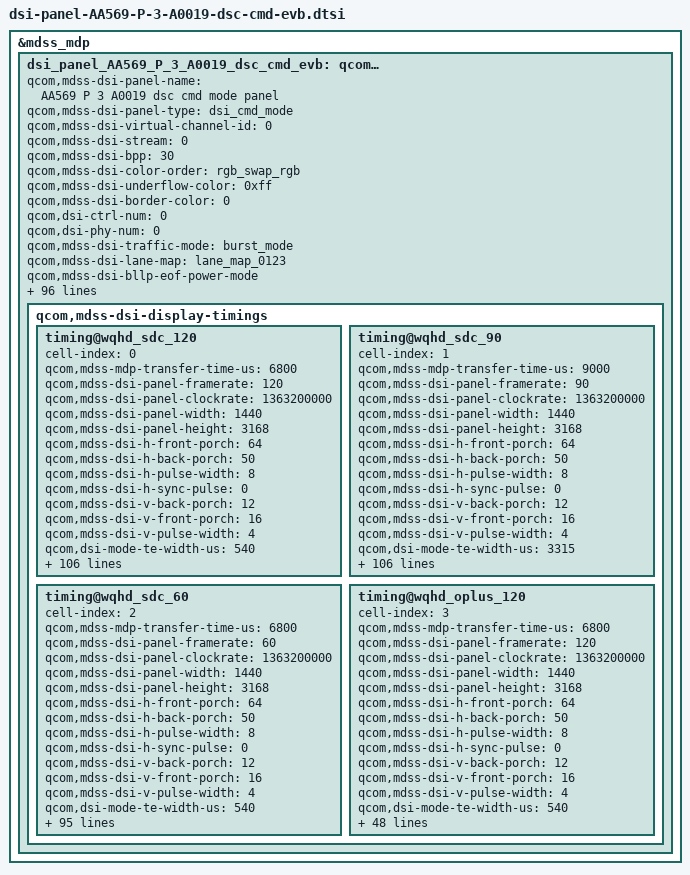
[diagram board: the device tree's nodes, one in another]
&mdss_mdp {
	dsi_panel_AA569_P_3_A0019_dsc_cmd_evb: qcom,mdss_dsi_panel_AA569_P_3_A0019_dsc_cmd_evb {
		qcom,mdss-dsi-panel-name = "AA569 P 3 A0019 dsc cmd mode panel";
		qcom,mdss-dsi-panel-type = "dsi_cmd_mode";
		qcom,mdss-dsi-virtual-channel-id = <0>;
		qcom,mdss-dsi-stream = <0>;
		qcom,mdss-dsi-bpp = <30>;
		qcom,mdss-dsi-color-order = "rgb_swap_rgb";
		qcom,mdss-dsi-underflow-color = <0xff>;
		qcom,mdss-dsi-border-color = <0>;
		qcom,dsi-ctrl-num = <0>;
		qcom,dsi-phy-num = <0>;
		qcom,mdss-dsi-traffic-mode = "burst_mode";
		qcom,mdss-dsi-lane-map = "lane_map_0123";
		qcom,mdss-dsi-bllp-eof-power-mode;
		qcom,mdss-dsi-bllp-power-mode;
		qcom,mdss-dsi-lane-0-state;
		qcom,mdss-dsi-lane-1-state;
		qcom,mdss-dsi-lane-2-state;
		qcom,mdss-dsi-lane-3-state;
		qcom,mdss-dsi-dma-trigger = "trigger_sw";
		qcom,mdss-dsi-mdp-trigger = "none";
		qcom,mdss-dsi-reset-sequence = <1 10>, <0 5>, <1 30>;
		qcom,mdss-pan-physical-width-dimension = <71>;
		qcom,mdss-pan-physical-height-dimension = <158>;
		qcom,mdss-dsi-te-check-enable;
		qcom,mdss-dsi-te-using-te-pin;
		qcom,mdss-dsi-te-pin-select = <1>;
		qcom,mdss-dsi-te-dcs-command = <1>;
		qcom,mdss-dsi-wr-mem-start = <0x2C>;
		qcom,mdss-dsi-wr-mem-continue = <0x3C>;
		//qcom,mdss-dsi-lp11-init;
		qcom,mdss-dsi-init-delay-us = <1000>;
		qcom,mdss-dsi-panel-jitter = <0x4 0x1>;
		/* HDR Setting */
		qcom,mdss-dsi-panel-hdr-enabled;
		qcom,mdss-dsi-panel-hdr-color-primaries = <15635 16450 34000 16000 13250 34500 7500 3000>;
		qcom,mdss-dsi-panel-peak-brightness = <14000000>;
		qcom,mdss-dsi-panel-average-brightness = <2000000>;
		qcom,mdss-dsi-panel-blackness-level = <2000>;

		qcom,mdss-dsi-display-timings {
			timing@wqhd_sdc_120 {
				#include "dsi-panel-AA569-P-3-A0019-common.dtsi"
				#include "dsi-panel-AA569-P-3-A0019-loading-effect-evb.dtsi"
				cell-index = <0>;
				qcom,mdss-mdp-transfer-time-us = <6800>;
				qcom,mdss-dsi-panel-framerate = <120>;
				qcom,mdss-dsi-panel-clockrate = <1363200000>;
				qcom,mdss-dsi-panel-width = <1440>;
				qcom,mdss-dsi-panel-height = <3168>;
				qcom,mdss-dsi-h-front-porch = <64>;
				qcom,mdss-dsi-h-back-porch = <50>;
				qcom,mdss-dsi-h-pulse-width = <8>;
				qcom,mdss-dsi-h-sync-pulse = <0>;
				qcom,mdss-dsi-v-back-porch = <12>;
				qcom,mdss-dsi-v-front-porch = <16>;
				qcom,mdss-dsi-v-pulse-width = <4>;
				qcom,dsi-mode-te-width-us = <540>;

				qcom,mdss-dsi-timing-switch-command = [
					//120Hz
					39 00 00 40 00 00 04 FF 5A A5 00
					15 00 00 40 00 00 02 60 00
					39 00 00 40 00 00 04 FF 5A A5 2D
					39 00 00 40 00 00 03 83 00 00
					15 00 00 40 00 00 02 F2 00
					39 00 00 40 00 00 04 FF 5A A5 02
					39 00 00 40 00 00 04 B0 01 80 00
					39 00 00 00 00 00 04 FF 5A A5 00
				];
				qcom,mdss-dsi-on-command = [
					//120Hz
					39 00 00 40 00 00 04 FF 5A A5 00
					15 00 00 40 00 00 02 60 00
					39 00 00 40 00 00 04 FF 5A A5 2D
					15 00 00 40 00 00 03 ED 03 00
					15 00 00 40 00 00 03 83 00 00
					15 00 00 40 00 00 02 F2 00
					39 00 00 40 00 00 04 FF 5A A5 02
					39 00 00 40 00 00 04 B0 01 80 00
					//light on
					39 00 00 40 00 00 04 FF 5A A5 00
					15 00 00 40 00 00 02 5A 01
					15 00 00 40 00 00 02 5B 80
					39 00 00 40 00 00 04 FF 5A A5 2D
					39 00 00 40 00 00 04 EC 01 FF FF
					39 00 00 40 00 00 03 ED D5 00
					39 00 00 40 00 00 03 93 A0 00
					39 00 00 40 00 00 03 94 40 00
					39 00 00 40 00 00 03 95 15 00
					39 00 00 40 00 00 03 96 FD 00
					39 00 00 40 00 00 04 FF 5A A5 02
					15 00 00 40 00 00 02 B6 00
					39 00 00 40 00 00 04 FF 5A A5 2D
					15 00 00 40 00 00 02 CE D4
					15 00 00 40 00 00 02 F7 40
					15 00 00 00 00 00 02 D9 41
					39 00 00 40 00 00 04 FF 5A A5 10
					15 00 00 40 00 00 02 83 2B
					39 00 00 40 00 00 04 FF 5A A5 20
					15 00 00 00 00 00 02 E1 80
					//esd check
					39 00 00 40 00 00 04 FF 5A A5 08
					15 00 00 40 00 00 02 D2 05
					15 00 00 40 00 00 02 D3 0D
					15 00 00 40 00 00 02 D4 40
					15 00 00 40 00 00 02 F5 55
					15 00 00 00 00 00 02 F6 18
					//120hz setting
					39 00 00 40 00 00 04 FF 5A A5 00
					15 00 00 40 00 00 02 5E 01				//Skip Frame en
					15 00 00 40 00 00 02 60 00				//Normal mode 1 = 120Hz.
					15 00 00 40 00 00 02 61 0D				//AOD in Mode 14 30Hz
					15 00 00 40 00 00 02 6D 01				//IRC Enable
					15 00 00 40 00 00 02 35 00
					15 00 00 40 00 00 02 53 20
					39 00 00 00 00 00 05 51 0D BB 0D BB
					/* spr in ap */
					39 00 00 40 00 00 04 FF 5A A5 14
					15 00 00 40 00 00 02 82 01		//SPR IN AP MODE
					39 00 00 40 00 00 04 FF 5A A5 07
					15 00 00 40 00 00 02 91 03		//CR CB SETTING
					15 00 00 40 00 00 02 8A 01         //DSC ON
					39 00 00 40 00 00 64 80 00 00 00 00 00 12 00 00 A0
					                     20 E0 0C 60 05 A0 00 0C 02 D0
					                     02 76 01 9A 01 1E 00 19 01 2B
					                     00 07 00 0C 08 BB 10 17 16 00
					                     0A E4 07 10 20 00 06 0F 0F 33
					                     0E 1C 2A 38 46 54 62 69 70 77
					                     79 7B 7D 7E 01 C2 22 00 2A 40
					                     32 BE 3A FC 3A FA 3A F8 3B 38
					                     3B 78 3B 76 4B B6 4B B6 4B F4
					                     5B F4 7C 34 01 00 00 00 00 00
					39 00 00 00 00 00 04 FF 5A A5 00
					//RCN
					39 00 00 40 00 00 04 FF 5A A5 17
					39 00 00 40 00 00 26 FA 01 20 00 3F 00 00 00 00 1C 20 00 3F 00 20 00 00 00 00 00 19 1C 20 00 00 00 20 00 00 00 00 14 19 1C 20 00 00 00
					39 00 00 40 00 00 0D FB 00 00 00 0A 50 FA 0A 50 64 00 00 00
					39 00 00 40 00 00 11 FC 00 00 00 00 00 00 00 00 00 00 00 00 00 00 00 00
					39 00 00 00 00 00 04 FF 5A A5 00
					//Hole
					39 00 00 40 00 00 04 FF 5A A5 13
					39 00 00 40 00 00 20 F7 01 00 00 00 19 00 00 19 00 00 00 00 00 00 00 00 19 00 00 00 19 00 19 19 00 19 00 00 19 00 19
					39 00 00 00 00 00 04 FF 5A A5 00

					15 00 00 00 78 00 02 11 00
					15 00 00 00 00 00 02 29 00
				];

				//qcom,panel-roi-alignment=<1080 44 1080 44 1080 44>;
				//qcom,partial-update-enabled = "single_roi";

				qcom,lm-split = <720 720>;
				qcom,mdss-dsc-slice-height = <22>;
				qcom,mdss-dsc-slice-width = <720>;
			};
			timing@wqhd_sdc_90 {
				#include "dsi-panel-AA569-P-3-A0019-common.dtsi"
				#include "dsi-panel-AA569-P-3-A0019-loading-effect-evb.dtsi"
				cell-index = <1>;
				qcom,mdss-mdp-transfer-time-us = <9000>;
				qcom,mdss-dsi-panel-framerate = <90>;
				qcom,mdss-dsi-panel-clockrate = <1363200000>;
				qcom,mdss-dsi-panel-width = <1440>;
				qcom,mdss-dsi-panel-height = <3168>;
				qcom,mdss-dsi-h-front-porch = <64>;
				qcom,mdss-dsi-h-back-porch = <50>;
				qcom,mdss-dsi-h-pulse-width = <8>;
				qcom,mdss-dsi-h-sync-pulse = <0>;
				qcom,mdss-dsi-v-back-porch = <12>;
				qcom,mdss-dsi-v-front-porch = <16>;
				qcom,mdss-dsi-v-pulse-width = <4>;
				qcom,dsi-mode-te-width-us = <3315>;

				qcom,mdss-dsi-timing-switch-command = [
					//90Hz
					39 00 00 40 00 00 04 FF 5A A5 00
					15 00 00 40 00 00 02 60 07
					39 00 00 40 00 00 04 FF 5A A5 2D
					39 00 00 40 00 00 03 8A 00 00
					15 00 00 40 00 00 02 F2 00
					39 00 00 40 00 00 04 FF 5A A5 02
					39 00 00 40 00 00 04 B0 00 80 00
					39 00 00 00 00 00 04 FF 5A A5 00
				];
				qcom,mdss-dsi-on-command = [
					//90Hz
					39 00 00 40 00 00 04 FF 5A A5 00
					15 00 00 40 00 00 02 60 07
					39 00 00 40 00 00 04 FF 5A A5 2D
					39 00 00 40 00 00 03 ED 0C 20
					39 00 00 40 00 00 03 8A 00 00
					15 00 00 40 00 00 02 84 00
					39 00 00 40 00 00 04 FF 5A A5 02
					39 00 00 40 00 00 04 B0 00 80 00
					//light on
					39 00 00 40 00 00 04 FF 5A A5 00
					15 00 00 40 00 00 02 5A 01
					15 00 00 40 00 00 02 5B 80
					39 00 00 40 00 00 04 FF 5A A5 2D
					39 00 00 40 00 00 04 EC 01 FF FF
					39 00 00 40 00 00 03 ED D5 00
					39 00 00 40 00 00 03 93 A0 00
					39 00 00 40 00 00 03 94 40 00
					39 00 00 40 00 00 03 95 15 00
					39 00 00 40 00 00 03 96 FD 00
					39 00 00 40 00 00 04 FF 5A A5 02
					15 00 00 40 00 00 02 B6 00
					39 00 00 40 00 00 04 FF 5A A5 2D
					15 00 00 40 00 00 02 CE D4
					15 00 00 40 00 00 02 F7 40
					15 00 00 40 00 00 02 D9 41
					39 00 00 40 00 00 04 FF 5A A5 10
					15 00 00 40 00 00 02 83 2B
					39 00 00 40 00 00 04 FF 5A A5 20
					15 00 00 00 00 00 02 E1 80
					//esd check
					39 00 00 40 00 00 04 FF 5A A5 08
					15 00 00 40 00 00 02 D2 05
					15 00 00 40 00 00 02 D3 0D
					15 00 00 40 00 00 02 D4 40
					15 00 00 40 00 00 02 F5 55
					15 00 00 00 00 00 02 F6 18
					//90hz setting
					39 00 00 40 00 00 04 FF 5A A5 00
					15 00 00 40 00 00 02 5E 01
					15 00 00 40 00 00 02 60 07
					15 00 00 40 00 00 02 61 0D
					15 00 00 40 00 00 02 6D 01
					15 00 00 40 00 00 02 35 00
					15 00 00 40 00 00 02 53 20
					39 00 00 00 00 00 05 51 0D BB 0D BB
					/* spr in ap */
					39 00 00 40 00 00 04 FF 5A A5 14
					15 00 00 40 00 00 02 82 01		//SPR IN AP MODE
					39 00 00 40 00 00 04 FF 5A A5 07
					15 00 00 40 00 00 02 91 03		//CR CB SETTING
					15 00 00 40 00 00 02 8A 01         //DSC ON
					39 00 00 40 00 00 64 80 00 00 00 00 00 12 00 00 A0
					                     20 E0 0C 60 05 A0 00 0C 02 D0
					                     02 76 01 9A 01 1E 00 19 01 2B
					                     00 07 00 0C 08 BB 10 17 16 00
					                     0A E4 07 10 20 00 06 0F 0F 33
					                     0E 1C 2A 38 46 54 62 69 70 77
					                     79 7B 7D 7E 01 C2 22 00 2A 40
					                     32 BE 3A FC 3A FA 3A F8 3B 38
					                     3B 78 3B 76 4B B6 4B B6 4B F4
					                     5B F4 7C 34 01 00 00 00 00 00
					39 00 00 00 00 00 04 FF 5A A5 00
					//RCN
					39 00 00 40 00 00 04 FF 5A A5 17
					39 00 00 40 00 00 26 FA 01 20 00 3F 00 00 00 00 1C 20 00 3F 00 20 00 00 00 00 00 19 1C 20 00 00 00 20 00 00 00 00 14 19 1C 20 00 00 00
					39 00 00 40 00 00 0D FB 00 00 00 0A 50 FA 0A 50 64 00 00 00
					39 00 00 40 00 00 11 FC 00 00 00 00 00 00 00 00 00 00 00 00 00 00 00 00
					39 00 00 00 00 00 04 FF 5A A5 00
					//Hole
					39 00 00 40 00 00 04 FF 5A A5 13
					39 00 00 40 00 00 20 F7 01 00 00 00 19 00 00 19 00 00 00 00 00 00 00 00 19 00 00 00 19 00 19 19 00 19 00 00 19 00 19
					39 00 00 00 00 00 04 FF 5A A5 00

					15 00 00 00 78 00 02 11 00
					15 00 00 00 00 00 02 29 00
				];

				//qcom,panel-roi-alignment=<1080 44 1080 44 1080 44>;
				//qcom,partial-update-enabled = "single_roi";

				qcom,lm-split = <720 720>;
				qcom,mdss-dsc-slice-height = <22>;
				qcom,mdss-dsc-slice-width = <720>;
			};
			timing@wqhd_sdc_60 {
				#include "dsi-panel-AA569-P-3-A0019-common.dtsi"
				#include "dsi-panel-AA569-P-3-A0019-loading-effect-evb.dtsi"
				cell-index = <2>;
				qcom,mdss-mdp-transfer-time-us = <6800>;
				qcom,mdss-dsi-panel-framerate = <60>;
				qcom,mdss-dsi-panel-clockrate = <1363200000>;
				qcom,mdss-dsi-panel-width = <1440>;
				qcom,mdss-dsi-panel-height = <3168>;
				qcom,mdss-dsi-h-front-porch = <64>;
				qcom,mdss-dsi-h-back-porch = <50>;
				qcom,mdss-dsi-h-pulse-width = <8>;
				qcom,mdss-dsi-h-sync-pulse = <0>;
				qcom,mdss-dsi-v-back-porch = <12>;
				qcom,mdss-dsi-v-front-porch = <16>;
				qcom,mdss-dsi-v-pulse-width = <4>;
				qcom,dsi-mode-te-width-us = <540>;

				/* Apollo vsync config, need to measure TE signal */
				oplus,apollo-panel-vsync-width = <8600>;

				qcom,mdss-dsi-timing-switch-command = [
					//60hz
					39 00 00 40 00 00 04 FF 5A A5 00
					15 00 00 40 00 00 02 60 00
					39 00 00 40 00 00 04 FF 5A A5 2D
					39 00 00 40 00 00 03 83 01 00
					15 00 00 40 00 00 02 F2 01
					39 00 00 40 00 00 04 FF 5A A5 02
					39 00 00 40 00 00 04 B0 01 80 00
					39 00 00 00 00 00 04 FF 5A A5 00
				];
				qcom,mdss-dsi-on-command = [
					//60Hz
					39 00 00 40 00 00 04 FF 5A A5 00
					15 00 00 40 00 00 02 60 00
					39 00 00 40 00 00 04 FF 5A A5 2D
					15 00 00 40 00 00 03 ED 03 00
					15 00 00 40 00 00 03 83 01 00
					15 00 00 40 00 00 02 F2 01
					39 00 00 40 00 00 04 FF 5A A5 02
					39 00 00 40 00 00 04 B0 01 80 00
					//light on
					39 00 00 40 00 00 04 FF 5A A5 00
					15 00 00 40 00 00 02 5A 01
					15 00 00 40 00 00 02 5B 80
					39 00 00 40 00 00 04 FF 5A A5 2D
					39 00 00 40 00 00 04 EC 01 FF FF
					39 00 00 40 00 00 03 ED D5 00
					39 00 00 40 00 00 03 93 A0 00
					39 00 00 40 00 00 03 94 40 00
					39 00 00 40 00 00 03 95 15 00
					39 00 00 40 00 00 03 96 FD 00
					39 00 00 40 00 00 04 FF 5A A5 02
					15 00 00 40 00 00 02 B6 00
					39 00 00 40 00 00 04 FF 5A A5 2D
					15 00 00 40 00 00 02 CE D4
					15 00 00 40 00 00 02 F7 40
					15 00 00 40 00 00 02 D9 41
					39 00 00 40 00 00 04 FF 5A A5 10
					15 00 00 40 00 00 02 83 2B
					39 00 00 40 00 00 04 FF 5A A5 20
					15 00 00 00 00 00 02 E1 80
					//esd check
					39 00 00 40 00 00 04 FF 5A A5 08
					15 00 00 40 00 00 02 D2 05
					15 00 00 40 00 00 02 D3 0D
					15 00 00 40 00 00 02 D4 40
					15 00 00 40 00 00 02 F5 55
					15 00 00 00 00 00 02 F6 18
					//60hz
					39 00 00 40 00 00 04 FF 5A A5 00
					15 00 00 40 00 00 02 5E 01
					15 00 00 40 00 00 02 60 00
					15 00 00 40 00 00 02 61 0D
					15 00 00 40 00 00 02 6D 01
					15 00 00 40 00 00 02 35 00
					15 00 00 40 00 00 02 53 20
					39 00 00 00 00 00 05 51 0D BB 0D BB
					/* spr in ap */
					39 00 00 40 00 00 04 FF 5A A5 14
					15 00 00 40 00 00 02 82 01		//SPR IN AP MODE
					39 00 00 40 00 00 04 FF 5A A5 07
					15 00 00 40 00 00 02 91 03		//CR CB SETTING
					15 00 00 40 00 00 02 8A 01         //DSC ON
					39 00 00 40 00 00 64 80 00 00 00 00 00 12 00 00 A0
					                     20 E0 0C 60 05 A0 00 0C 02 D0
					                     02 76 01 9A 01 1E 00 19 01 2B
					                     00 07 00 0C 08 BB 10 17 16 00
					                     0A E4 07 10 20 00 06 0F 0F 33
					                     0E 1C 2A 38 46 54 62 69 70 77
					                     79 7B 7D 7E 01 C2 22 00 2A 40
					                     32 BE 3A FC 3A FA 3A F8 3B 38
					                     3B 78 3B 76 4B B6 4B B6 4B F4
					                     5B F4 7C 34 01 00 00 00 00 00
					39 00 00 00 00 00 04 FF 5A A5 00
					//RCN
					39 00 00 40 00 00 04 FF 5A A5 17
					39 00 00 40 00 00 26 FA 01 20 00 3F 00 00 00 00 1C 20 00 3F 00 20 00 00 00 00 00 19 1C 20 00 00 00 20 00 00 00 00 14 19 1C 20 00 00 00
					39 00 00 40 00 00 0D FB 00 00 00 0A 50 FA 0A 50 64 00 00 00
					39 00 00 40 00 00 11 FC 00 00 00 00 00 00 00 00 00 00 00 00 00 00 00 00
					39 00 00 00 00 00 04 FF 5A A5 00
					//Hole
					39 00 00 40 00 00 04 FF 5A A5 13
					39 00 00 40 00 00 20 F7 01 00 00 00 19 00 00 19 00 00 00 00 00 00 00 00 19 00 00 00 19 00 19 19 00 19 00 00 19 00 19
					39 00 00 00 00 00 04 FF 5A A5 00

					15 00 00 00 78 00 02 11 00
					15 00 00 00 00 00 02 29 00
				];

				//qcom,panel-roi-alignment=<1080 44 1080 44 1080 44>;
				//qcom,partial-update-enabled = "single_roi";

				qcom,lm-split = <720 720>;
				qcom,mdss-dsc-slice-height = <22>;
				qcom,mdss-dsc-slice-width = <720>;
				oplus,apollo-panel-async-bl-delay = <9000>;
			};
			timing@wqhd_oplus_120 {
				#include "dsi-panel-AA569-P-3-A0019-common.dtsi"
				#include "dsi-panel-AA569-P-3-A0019-loading-effect-evb.dtsi"
				cell-index = <3>;
				qcom,mdss-mdp-transfer-time-us = <6800>;
				qcom,mdss-dsi-panel-framerate = <120>;
				qcom,mdss-dsi-panel-clockrate = <1363200000>;
				qcom,mdss-dsi-panel-width = <1440>;
				qcom,mdss-dsi-panel-height = <3168>;
				qcom,mdss-dsi-h-front-porch = <64>;
				qcom,mdss-dsi-h-back-porch = <50>;
				qcom,mdss-dsi-h-pulse-width = <8>;
				qcom,mdss-dsi-h-sync-pulse = <0>;
				qcom,mdss-dsi-v-back-porch = <12>;
				qcom,mdss-dsi-v-front-porch = <16>;
				qcom,mdss-dsi-v-pulse-width = <4>;
				qcom,dsi-mode-te-width-us = <540>;

				qcom,mdss-dsi-timing-switch-command = [
					//OA-120Hz
					39 00 00 40 00 00 04 FF 5A A5 00
					15 00 00 40 00 00 02 60 00
					39 00 00 40 00 00 04 FF 5A A5 2D
					39 00 00 40 00 00 04 EC 01 0A 20
					39 00 00 40 00 00 03 ED 03 00
					39 00 00 40 00 00 19 EF 00 00 00 00 00 00 00 00 00 00 00 00 00 00 00 01 00 00 00 00 02 00 00 00
					15 00 00 40 00 00 02 F2 00
					39 00 00 40 00 00 04 FF 5A A5 02
					39 00 00 40 00 00 05 C0 03 00 02 00
					39 00 00 40 00 00 04 B0 00 88 00
					39 00 00 40 00 00 04 FF 5A A5 4F
					15 00 00 00 00 00 02 8B 78
				];
				qcom,mdss-dsi-on-command = [
					//OA-120Hz
					39 00 00 40 00 00 04 FF 5A A5 00
					15 00 00 40 00 00 02 60 00
					39 00 00 40 00 00 04 FF 5A A5 2D
					15 00 00 40 00 00 04 EC 01 0A 20
					15 00 00 40 00 00 03 ED 03 00
					15 00 00 40 00 00 19 EF 00 00 00 00 00 00 00 00 00 00 00 00 00 00 00 01 00 00 00 00 02 00 00 00
					15 00 00 40 00 00 02 F2 01
					39 00 00 40 00 00 04 FF 5A A5 02
					39 00 00 40 00 00 05 C0 03 00 02 00
					39 00 00 40 00 00 04 B0 00 88 00
					//light on
					39 00 00 40 00 00 04 FF 5A A5 00
					15 00 00 40 00 00 02 5A 01
					15 00 00 40 00 00 02 5B 80
					39 00 00 40 00 00 04 FF 5A A5 2D
					39 00 00 40 00 00 04 EC 01 FF FF
					39 00 00 40 00 00 03 ED D5 00
					39 00 00 40 00 00 03 93 A0 00
					39 00 00 40 00 00 03 94 40 00
					39 00 00 40 00 00 03 95 15 00
					39 00 00 40 00 00 03 96 FD 00
					39 00 00 40 00 00 04 FF 5A A5 02
					15 00 00 40 00 00 02 B6 00
					39 00 00 40 00 00 04 FF 5A A5 2D
					15 00 00 40 00 00 02 CE D4
					15 00 00 40 00 00 02 F7 40
					15 00 00 40 00 00 02 D9 41
					39 00 00 40 00 00 04 FF 5A A5 10
					15 00 00 40 00 00 02 83 2B
					39 00 00 40 00 00 04 FF 5A A5 20
					15 00 00 00 00 00 02 E1 80
					//esd check
					39 00 00 40 00 00 04 FF 5A A5 08
					15 00 00 40 00 00 02 D2 05
					15 00 00 40 00 00 02 D3 0D
					15 00 00 40 00 00 02 D4 40
					15 00 00 40 00 00 02 F5 55
					15 00 00 00 00 00 02 F6 18
					//oa 120
					39 00 00 40 00 00 04 FF 5A A5 00
					15 00 00 40 00 00 02 5E 01
					15 00 00 40 00 00 02 60 00
					15 00 00 40 00 00 02 61 0D
					15 00 00 40 00 00 02 6D 01
					15 00 00 40 00 00 02 35 00
					15 00 00 40 00 00 02 53 20
					39 00 00 00 00 00 05 51 0D BB 0D BB
					/* spr in ap */
					39 00 00 40 00 00 04 FF 5A A5 14
					15 00 00 40 00 00 02 82 01		//SPR IN AP MODE
					39 00 00 40 00 00 04 FF 5A A5 07
					15 00 00 40 00 00 02 91 03		//CR CB SETTING
					15 00 00 40 00 00 02 8A 01         //DSC ON
					39 00 00 40 00 00 64 80 00 00 00 00 00 12 00 00 A0
					                     20 E0 0C 60 05 A0 00 0C 02 D0
					                     02 76 01 9A 01 1E 00 19 01 2B
					                     00 07 00 0C 08 BB 10 17 16 00
					                     0A E4 07 10 20 00 06 0F 0F 33
					                     0E 1C 2A 38 46 54 62 69 70 77
					                     79 7B 7D 7E 01 C2 22 00 2A 40
					                     32 BE 3A FC 3A FA 3A F8 3B 38
					                     3B 78 3B 76 4B B6 4B B6 4B F4
					                     5B F4 7C 34 01 00 00 00 00 00
					39 00 00 00 00 00 04 FF 5A A5 00
					//RCN
					39 00 00 40 00 00 04 FF 5A A5 17
					39 00 00 40 00 00 26 FA 01 20 00 3F 00 00 00 00 1C 20 00 3F 00 20 00 00 00 00 00 19 1C 20 00 00 00 20 00 00 00 00 14 19 1C 20 00 00 00
					39 00 00 40 00 00 0D FB 00 00 00 0A 50 FA 0A 50 64 00 00 00
					39 00 00 40 00 00 11 FC 00 00 00 00 00 00 00 00 00 00 00 00 00 00 00 00
					39 00 00 00 00 00 04 FF 5A A5 00
					//Hole
					39 00 00 40 00 00 04 FF 5A A5 13
					39 00 00 40 00 00 20 F7 01 00 00 00 19 00 00 19 00 00 00 00 00 00 00 00 19 00 00 00 19 00 19 19 00 19 00 00 19 00 19
					39 00 00 00 00 00 04 FF 5A A5 00

					15 00 00 00 78 00 02 11 00
					15 00 00 00 00 00 02 29 00
				];

				//qcom,panel-roi-alignment=<1080 44 1080 44 1080 44>;
				//qcom,partial-update-enabled = "single_roi";

				qcom,lm-split = <720 720>;
				qcom,mdss-dsc-slice-height = <22>;
				qcom,mdss-dsc-slice-width = <720>;
			};
		};
	};
};

&dsi_panel_AA569_P_3_A0019_dsc_cmd_evb {
	qcom,ulps-enabled;
	qcom,dsi-select-clocks = "pll_byte_clk0", "pll_dsi_clk0";
	qcom,mdss-dsi-display-timings {
		timing@wqhd_sdc_120 {
			qcom,mdss-dsi-panel-phy-timings = [00 2C 0C 0C 1D 1A 0C 0C 0B 02 04 00 24 11];
			qcom,display-topology = <1 1 1>,<2 2 1>;
			qcom,default-topology-index = <1>;
			qcom,partial-update-enabled = "single_roi";
			qcom,panel-roi-alignment = <1440 22 1440 22 1440 22>;
		};
		timing@wqhd_sdc_90 {
			qcom,mdss-dsi-panel-phy-timings = [00 2C 0C 0C 1D 1A 0C 0C 0B 02 04 00 24 11];
			qcom,display-topology = <1 1 1>,<2 2 1>;
			qcom,default-topology-index = <1>;
			qcom,partial-update-enabled = "single_roi";
			qcom,panel-roi-alignment = <1440 22 1440 22 1440 22>;
		};
		timing@wqhd_sdc_60 {
			qcom,mdss-dsi-panel-phy-timings = [00 2C 0C 0C 1D 1A 0C 0C 0B 02 04 00 24 11];
			qcom,display-topology = <1 1 1>,<2 2 1>;
			qcom,default-topology-index = <1>;
			qcom,partial-update-enabled = "single_roi";
			qcom,panel-roi-alignment = <1440 22 1440 22 1440 22>;
		};
		timing@wqhd_oplus_120 {
			qcom,mdss-dsi-panel-phy-timings = [00 2C 0C 0C 1D 1A 0C 0C 0B 02 04 00 24 11];
			qcom,display-topology = <1 1 1>,<2 2 1>;
			qcom,default-topology-index = <1>;
			qcom,partial-update-enabled = "single_roi";
			qcom,panel-roi-alignment = <1440 22 1440 22 1440 22>;
		};
	};
};

&dsi_panel_AA569_P_3_A0019_dsc_cmd_evb {
	qcom,mdss-dsi-display-timings {
		timing@wqhd_sdc_120 {
			/* SDC ADFR */
			qcom,mdss-dsi-h-sync-skew = <0>;
			oplus,adfr-min-fps-mapping-table = <120 60 30 20 10 5 1>;
			oplus,adfr-idle-off-min-fps = <20>;
			qcom,mdss-dsi-adfr-pre-switch-command = [
				39 00 00 40 00 00 04 FF 5A A5 2D
				39 00 00 40 00 00 03 ED 01 00
				39 00 00 40 00 00 03 83 00 00
				39 00 00 40 00 00 03 8E 00 00
				15 00 00 40 00 00 02 97 00
				15 00 00 40 00 00 02 98 00
				39 00 00 40 00 00 03 A0 00 00
				39 00 00 00 00 00 04 FF 5A A5 00
			];
			qcom,mdss-dsi-adfr-min-fps-0-command = [
				/*120Hz*/
				39 00 00 40 00 00 04 FF 5A A5 2D
				39 00 00 40 00 00 03 ED 01 00
				39 00 00 40 00 00 03 83 00 00
				15 00 00 40 00 00 02 97 00
				15 00 00 40 00 00 02 98 00
				39 00 00 40 00 00 03 A0 00 00
				39 00 00 00 00 00 04 FF 5A A5 00
			];
			qcom,mdss-dsi-adfr-min-fps-1-command = [
				/*60Hz*/
				39 00 00 40 00 00 04 FF 5A A5 2D
				39 00 00 40 00 00 03 ED 01 00
				39 00 00 40 00 00 03 83 01 00
				15 00 00 40 00 00 02 97 00
				15 00 00 40 00 00 02 98 01
				39 00 00 40 00 00 03 A0 00 00
				39 00 00 00 00 00 04 FF 5A A5 00
			];
			qcom,mdss-dsi-adfr-min-fps-2-command = [
				/*30Hz*/
				39 00 00 40 00 00 04 FF 5A A5 2D
				39 00 00 40 00 00 03 ED 01 00
				39 00 00 40 00 00 03 83 03 00
				15 00 00 40 00 00 02 97 00
				15 00 00 40 00 00 02 98 03
				39 00 00 40 00 00 03 A0 00 00
				39 00 00 00 00 00 04 FF 5A A5 00
			];
			qcom,mdss-dsi-adfr-min-fps-3-command = [
				/*20Hz*/
				39 00 00 40 00 00 04 FF 5A A5 2D
				39 00 00 40 00 00 03 ED 01 00
				39 00 00 40 00 00 03 83 05 00
				15 00 00 40 00 00 02 97 00
				15 00 00 40 00 00 02 98 03
				39 00 00 40 00 00 03 A0 00 00
				39 00 00 00 00 00 04 FF 5A A5 00
			];
			qcom,mdss-dsi-adfr-min-fps-4-command = [
				/*10Hz*/
				39 00 00 40 00 00 04 FF 5A A5 2D
				39 00 00 40 00 00 03 ED 01 00
				39 00 00 40 00 00 03 83 0B 00
				15 00 00 40 00 00 02 97 00
				15 00 00 40 00 00 02 98 03
				39 00 00 40 00 00 03 A0 00 00
				39 00 00 00 00 00 04 FF 5A A5 00
			];
			qcom,mdss-dsi-adfr-min-fps-5-command = [
				/*5Hz*/
				39 00 00 40 00 00 04 FF 5A A5 2D
				39 00 00 40 00 00 03 ED 01 00
				39 00 00 40 00 00 03 83 17 00
				15 00 00 40 00 00 02 97 00
				15 00 00 40 00 00 02 98 03
				39 00 00 40 00 00 03 A0 00 00
				39 00 00 00 00 00 04 FF 5A A5 00
			];
			qcom,mdss-dsi-adfr-min-fps-6-command = [
				/*1Hz*/
				39 00 00 40 00 00 04 FF 5A A5 2D
				39 00 00 40 00 00 03 ED 01 00
				39 00 00 40 00 00 03 83 77 00
				15 00 00 40 00 00 02 97 02
				15 00 00 40 00 00 02 98 03
				15 00 00 40 00 00 02 99 0B
				15 00 00 40 00 00 02 9A 17
				39 00 00 40 00 00 03 A0 00 02
				15 00 00 40 00 00 02 A1 02
				39 00 00 00 00 00 04 FF 5A A5 00
			];
			qcom,mdss-dsi-hpwm-adfr-min-fps-0-command = [
				/*120Hz*/
				39 00 00 40 00 00 04 FF 5A A5 2D
				39 00 00 40 00 00 03 ED 01 00
				39 00 00 40 00 00 03 83 00 00
				15 00 00 40 00 00 02 97 00
				15 00 00 40 00 00 02 98 00
				39 00 00 40 00 00 03 A0 00 00
				39 00 00 00 00 00 04 FF 5A A5 00
			];

			qcom,mdss-dsi-hpwm-adfr-min-fps-1-command = [
				39 00 00 40 00 00 04 FF 5A A5 2D
				39 00 00 40 00 00 03 ED 01 00
				39 00 00 40 00 00 03 83 01 00
				15 00 00 40 00 00 02 97 00
				15 00 00 40 00 00 02 98 01
				39 00 00 40 00 00 03 A0 00 00
				39 00 00 00 00 00 04 FF 5A A5 00
			];

			qcom,mdss-dsi-hpwm-adfr-min-fps-2-command = [
				39 00 00 40 00 00 04 FF 5A A5 2D
				39 00 00 40 00 00 03 ED 01 00
				39 00 00 40 00 00 03 83 03 00
				15 00 00 40 00 00 02 97 00
				15 00 00 40 00 00 02 98 03
				39 00 00 40 00 00 03 A0 00 00
				39 00 00 00 00 00 04 FF 5A A5 00
			];

			qcom,mdss-dsi-hpwm-adfr-min-fps-3-command = [
				39 00 00 40 00 00 04 FF 5A A5 2D
				39 00 00 40 00 00 03 ED 01 00
				39 00 00 40 00 00 03 83 05 00
				15 00 00 40 00 00 02 97 00
				15 00 00 40 00 00 02 98 03
				39 00 00 40 00 00 03 A0 00 00
				39 00 00 00 00 00 04 FF 5A A5 00
			];

			qcom,mdss-dsi-hpwm-adfr-min-fps-4-command = [
				//10Hz
				39 00 00 40 00 00 04 FF 5A A5 2D
				39 00 00 40 00 00 03 ED 01 00
				39 00 00 40 00 00 03 83 0B 00
				15 00 00 40 00 00 02 97 00
				15 00 00 40 00 00 02 98 03
				39 00 00 40 00 00 03 A0 00 00
				39 00 00 00 00 00 04 FF 5A A5 00
			];

			qcom,mdss-dsi-hpwm-adfr-min-fps-5-command = [
				39 00 00 40 00 00 04 FF 5A A5 2D
				39 00 00 40 00 00 03 ED 01 00
				39 00 00 40 00 00 03 83 17 00
				15 00 00 40 00 00 02 97 00
				15 00 00 40 00 00 02 98 03
				39 00 00 40 00 00 03 A0 00 00
				39 00 00 00 00 00 04 FF 5A A5 00
			];

			qcom,mdss-dsi-hpwm-adfr-min-fps-6-command = [
				39 00 00 40 00 00 04 FF 5A A5 2D
				39 00 00 40 00 00 03 ED 01 00
				39 00 00 40 00 00 03 83 77 00
				15 00 00 40 00 00 02 97 02
				15 00 00 40 00 00 02 98 03
				15 00 00 40 00 00 02 99 0B
				15 00 00 40 00 00 02 9A 17
				39 00 00 40 00 00 03 A0 00 02
				15 00 00 40 00 00 02 A1 02
				39 00 00 00 00 00 04 FF 5A A5 00
			];
			qcom,mdss-dsi-bigdc-adfr-min-fps-0-command = [
				/*120Hz*/
				39 00 00 40 00 00 04 FF 5A A5 2D
				39 00 00 40 00 00 03 ED 01 00
				39 00 00 40 00 00 03 8E 00 00
				15 00 00 40 00 00 02 97 00
				15 00 00 40 00 00 02 98 00
				39 00 00 40 00 00 03 A0 00 00
				39 00 00 00 00 00 04 FF 5A A5 00
			];

			qcom,mdss-dsi-bigdc-adfr-min-fps-1-command = [
				39 00 00 40 00 00 04 FF 5A A5 2D
				39 00 00 40 00 00 03 ED 01 00
				39 00 00 40 00 00 03 8E 01 00
				15 00 00 40 00 00 02 97 00
				15 00 00 40 00 00 02 98 01
				39 00 00 40 00 00 03 A0 00 00
				39 00 00 00 00 00 04 FF 5A A5 00
			];

			qcom,mdss-dsi-bigdc-adfr-min-fps-2-command = [
				39 00 00 40 00 00 04 FF 5A A5 2D
				39 00 00 40 00 00 03 ED 01 00
				39 00 00 40 00 00 03 8E 03 00
				15 00 00 40 00 00 02 97 00
				15 00 00 40 00 00 02 98 03
				39 00 00 40 00 00 03 A0 00 00
				39 00 00 00 00 00 04 FF 5A A5 00
			];

			qcom,mdss-dsi-bigdc-adfr-min-fps-3-command = [
				39 00 00 40 00 00 04 FF 5A A5 2D
				39 00 00 40 00 00 03 ED 01 00
				39 00 00 40 00 00 03 8E 05 00
				15 00 00 40 00 00 02 97 00
				15 00 00 40 00 00 02 98 03
				39 00 00 40 00 00 03 A0 00 00
				39 00 00 00 00 00 04 FF 5A A5 00
			];

			qcom,mdss-dsi-bigdc-adfr-min-fps-4-command = [
				//10Hz
				39 00 00 40 00 00 04 FF 5A A5 2D
				39 00 00 40 00 00 03 ED 01 00
				39 00 00 40 00 00 03 8E 0B 00
				15 00 00 40 00 00 02 97 00
				15 00 00 40 00 00 02 98 03
				39 00 00 40 00 00 03 A0 00 00
				39 00 00 00 00 00 04 FF 5A A5 00
			];

			qcom,mdss-dsi-bigdc-adfr-min-fps-5-command = [
				39 00 00 40 00 00 04 FF 5A A5 2D
				39 00 00 40 00 00 03 ED 01 00
				39 00 00 40 00 00 03 8E 17 00
				15 00 00 40 00 00 02 97 00
				15 00 00 40 00 00 02 98 03
				39 00 00 40 00 00 03 A0 00 00
				39 00 00 00 00 00 04 FF 5A A5 00
			];

			qcom,mdss-dsi-bigdc-adfr-min-fps-6-command = [
				39 00 00 40 00 00 04 FF 5A A5 2D
				39 00 00 40 00 00 03 ED 01 00
				39 00 00 40 00 00 03 8E 77 00
				15 00 00 40 00 00 02 97 02
				15 00 00 40 00 00 02 98 03
				15 00 00 40 00 00 02 99 0B
				15 00 00 40 00 00 02 9A 17
				39 00 00 40 00 00 03 A0 00 02
				15 00 00 40 00 00 02 A1 02
				39 00 00 00 00 00 04 FF 5A A5 00
			];

			qcom,mdss-dsi-adfr-pre-switch-command-state = "dsi_hs_mode";
			qcom,mdss-dsi-adfr-min-fps-0-command-state = "dsi_hs_mode";
			qcom,mdss-dsi-adfr-min-fps-1-command-state = "dsi_hs_mode";
			qcom,mdss-dsi-adfr-min-fps-2-command-state = "dsi_hs_mode";
			qcom,mdss-dsi-adfr-min-fps-3-command-state = "dsi_hs_mode";
			qcom,mdss-dsi-adfr-min-fps-4-command-state = "dsi_hs_mode";
			qcom,mdss-dsi-adfr-min-fps-5-command-state = "dsi_hs_mode";
			qcom,mdss-dsi-adfr-min-fps-6-command-state = "dsi_hs_mode";
			qcom,mdss-dsi-hpwm-adfr-min-fps-0-command-state = "dsi_hs_mode";
			qcom,mdss-dsi-hpwm-adfr-min-fps-1-command-state = "dsi_hs_mode";
			qcom,mdss-dsi-hpwm-adfr-min-fps-2-command-state = "dsi_hs_mode";
			qcom,mdss-dsi-hpwm-adfr-min-fps-3-command-state = "dsi_hs_mode";
			qcom,mdss-dsi-hpwm-adfr-min-fps-4-command-state = "dsi_hs_mode";
			qcom,mdss-dsi-hpwm-adfr-min-fps-5-command-state = "dsi_hs_mode";
			qcom,mdss-dsi-hpwm-adfr-min-fps-6-command-state = "dsi_hs_mode";
			qcom,mdss-dsi-bigdc-adfr-min-fps-0-command-state = "dsi_hs_mode";
			qcom,mdss-dsi-bigdc-adfr-min-fps-1-command-state = "dsi_hs_mode";
			qcom,mdss-dsi-bigdc-adfr-min-fps-2-command-state = "dsi_hs_mode";
			qcom,mdss-dsi-bigdc-adfr-min-fps-3-command-state = "dsi_hs_mode";
			qcom,mdss-dsi-bigdc-adfr-min-fps-4-command-state = "dsi_hs_mode";
			qcom,mdss-dsi-bigdc-adfr-min-fps-5-command-state = "dsi_hs_mode";
			qcom,mdss-dsi-bigdc-adfr-min-fps-6-command-state = "dsi_hs_mode";
		};
		timing@wqhd_sdc_90 {
			/* SDC ADFR */
			qcom,mdss-dsi-h-sync-skew = <0>;
			oplus,adfr-fakeframe-config = <0>;
			oplus,adfr-min-fps-mapping-table = <90 45 30 15 10 5 1>;
			qcom,mdss-dsi-adfr-pre-switch-command = [
				39 00 00 40 00 00 04 FF 5A A5 2D
				39 00 00 40 00 00 03 ED 04 00
				39 00 00 40 00 00 03 8A 00 00
				39 00 00 40 00 00 03 8F 00 00
				15 00 00 40 00 00 02 A4 00
				15 00 00 40 00 00 02 A5 00
				39 00 00 40 00 00 03 AD 00 00
				39 00 00 00 00 00 04 FF 5A A5 00
			];
			qcom,mdss-dsi-adfr-min-fps-0-command = [
				/*90Hz*/
				39 00 00 40 00 00 04 FF 5A A5 2D
				39 00 00 40 00 00 03 ED 04 00
				39 00 00 40 00 00 03 8A 00 00
				15 00 00 40 00 00 02 A4 00
				15 00 00 40 00 00 02 A5 00
				39 00 00 40 00 00 03 AD 00 00
				39 00 00 00 00 00 04 FF 5A A5 00
			];
			qcom,mdss-dsi-adfr-min-fps-1-command = [
				/*45Hz*/
				39 00 00 40 00 00 04 FF 5A A5 2D
				39 00 00 40 00 00 03 ED 04 00
				39 00 00 40 00 00 03 8A 01 00
				15 00 00 40 00 00 02 A4 00
				15 00 00 40 00 00 02 A5 01
				39 00 00 40 00 00 03 AD 00 00
				39 00 00 00 00 00 04 FF 5A A5 00
			];
			qcom,mdss-dsi-adfr-min-fps-2-command = [
				/*30Hz*/
				39 00 00 40 00 00 04 FF 5A A5 2D
				39 00 00 40 00 00 03 ED 04 00
				39 00 00 40 00 00 03 8A 02 00
				15 00 00 40 00 00 02 A4 00
				15 00 00 40 00 00 02 A5 02
				39 00 00 40 00 00 03 AD 00 00
				39 00 00 00 00 00 04 FF 5A A5 00
			];
			qcom,mdss-dsi-adfr-min-fps-3-command = [
				/*15Hz*/
				39 00 00 40 00 00 04 FF 5A A5 2D
				39 00 00 40 00 00 03 ED 04 00
				39 00 00 40 00 00 03 8A 05 00
				15 00 00 40 00 00 02 A4 00
				15 00 00 40 00 00 02 A5 02
				39 00 00 40 00 00 03 AD 00 00
				39 00 00 00 00 00 04 FF 5A A5 00
			];
			qcom,mdss-dsi-adfr-min-fps-4-command = [
				/*10Hz*/
				39 00 00 40 00 00 04 FF 5A A5 2D
				39 00 00 40 00 00 03 ED 04 00
				39 00 00 40 00 00 03 8A 08 00
				15 00 00 40 00 00 02 A4 00
				15 00 00 40 00 00 02 A5 02
				39 00 00 40 00 00 03 AD 00 00
				39 00 00 00 00 00 04 FF 5A A5 00
			];
			qcom,mdss-dsi-adfr-min-fps-5-command = [
				/*5Hz*/
				39 00 00 40 00 00 04 FF 5A A5 2D
				39 00 00 40 00 00 03 ED 04 00
				39 00 00 40 00 00 03 8A 11 00
				15 00 00 40 00 00 02 A4 00
				15 00 00 40 00 00 02 A5 02
				39 00 00 40 00 00 03 AD 00 00
				39 00 00 00 00 00 04 FF 5A A5 00
			];
			qcom,mdss-dsi-adfr-min-fps-6-command = [
				/*1Hz*/
				39 00 00 40 00 00 04 FF 5A A5 2D
				39 00 00 40 00 00 03 ED 04 00
				39 00 00 40 00 00 03 8A 59 00
				15 00 00 40 00 00 02 A4 02
				15 00 00 40 00 00 02 A5 02
				15 00 00 40 00 00 02 A6 08
				15 00 00 40 00 00 02 A7 11
				39 00 00 40 00 00 03 AD 00 02
				15 00 00 40 00 00 02 AE 02
				39 00 00 00 00 00 04 FF 5A A5 00
			];
			qcom,mdss-dsi-hpwm-adfr-min-fps-0-command = [
				/*90Hz*/
				39 00 00 40 00 00 04 FF 5A A5 2D
				39 00 00 40 00 00 03 ED 04 00
				39 00 00 40 00 00 03 8A 00 00
				15 00 00 40 00 00 02 A4 00
				15 00 00 40 00 00 02 A5 00
				39 00 00 40 00 00 03 AD 00 00
				39 00 00 00 00 00 04 FF 5A A5 00
			];

			qcom,mdss-dsi-hpwm-adfr-min-fps-1-command = [
				//45Hz
				39 00 00 40 00 00 04 FF 5A A5 2D
				39 00 00 40 00 00 03 ED 04 00
				39 00 00 40 00 00 03 8A 01 00
				15 00 00 40 00 00 02 A4 00
				15 00 00 40 00 00 02 A5 01
				39 00 00 40 00 00 03 AD 00 00
				39 00 00 00 00 00 04 FF 5A A5 00
			];

			qcom,mdss-dsi-hpwm-adfr-min-fps-2-command = [
				//30Hz
				39 00 00 40 00 00 04 FF 5A A5 2D
				39 00 00 40 00 00 03 ED 04 00
				39 00 00 40 00 00 03 8A 02 00
				15 00 00 40 00 00 02 A4 00
				15 00 00 40 00 00 02 A5 02
				39 00 00 40 00 00 03 AD 00 00
				39 00 00 00 00 00 04 FF 5A A5 00
			];

			qcom,mdss-dsi-hpwm-adfr-min-fps-3-command = [
				//15Hz
				39 00 00 40 00 00 04 FF 5A A5 2D
				39 00 00 40 00 00 03 ED 04 00
				39 00 00 40 00 00 03 8A 05 00
				15 00 00 40 00 00 02 A4 00
				15 00 00 40 00 00 02 A5 02
				39 00 00 40 00 00 03 AD 00 00
				39 00 00 00 00 00 04 FF 5A A5 00
			];

			qcom,mdss-dsi-hpwm-adfr-min-fps-4-command = [
				//10Hz
				39 00 00 40 00 00 04 FF 5A A5 2D
				39 00 00 40 00 00 03 ED 04 00
				39 00 00 40 00 00 03 8A 08 00
				15 00 00 40 00 00 02 A4 00
				15 00 00 40 00 00 02 A5 02
				39 00 00 40 00 00 03 AD 00 00
				39 00 00 00 00 00 04 FF 5A A5 00
			];

			qcom,mdss-dsi-hpwm-adfr-min-fps-5-command = [
				//5Hz
				39 00 00 40 00 00 04 FF 5A A5 2D
				39 00 00 40 00 00 03 ED 04 00
				39 00 00 40 00 00 03 8A 11 00
				15 00 00 40 00 00 02 A4 00
				15 00 00 40 00 00 02 A5 02
				39 00 00 40 00 00 03 AD 00 00
				39 00 00 00 00 00 04 FF 5A A5 00
			];

			qcom,mdss-dsi-hpwm-adfr-min-fps-6-command = [
				//1Hz
				39 00 00 40 00 00 04 FF 5A A5 2D
				39 00 00 40 00 00 03 ED 04 00
				39 00 00 40 00 00 03 8A 59 00
				15 00 00 40 00 00 02 A4 02
				15 00 00 40 00 00 02 A5 02
				15 00 00 40 00 00 02 A6 08
				15 00 00 40 00 00 02 A7 11
				39 00 00 40 00 00 03 AD 00 02
				15 00 00 40 00 00 02 AE 02
				39 00 00 00 00 00 04 FF 5A A5 00
			];
			qcom,mdss-dsi-bigdc-adfr-min-fps-0-command = [
				/*90Hz*/
				39 00 00 40 00 00 04 FF 5A A5 2D
				39 00 00 40 00 00 03 ED 04 00
				39 00 00 40 00 00 03 8F 00 00
				15 00 00 40 00 00 02 A4 00
				15 00 00 40 00 00 02 A5 00
				39 00 00 40 00 00 03 AD 00 00
				39 00 00 00 00 00 04 FF 5A A5 00
			];

			qcom,mdss-dsi-bigdc-adfr-min-fps-1-command = [
				//45Hz
				39 00 00 40 00 00 04 FF 5A A5 2D
				39 00 00 40 00 00 03 ED 04 00
				39 00 00 40 00 00 03 8F 01 00
				15 00 00 40 00 00 02 A4 00
				15 00 00 40 00 00 02 A5 01
				39 00 00 40 00 00 03 AD 00 00
				39 00 00 00 00 00 04 FF 5A A5 00
			];

			qcom,mdss-dsi-bigdc-adfr-min-fps-2-command = [
				//30Hz
				39 00 00 40 00 00 04 FF 5A A5 2D
				39 00 00 40 00 00 03 ED 04 00
				39 00 00 40 00 00 03 8F 02 00
				15 00 00 40 00 00 02 A4 00
				15 00 00 40 00 00 02 A5 02
				39 00 00 40 00 00 03 AD 00 00
				39 00 00 00 00 00 04 FF 5A A5 00
			];

			qcom,mdss-dsi-bigdc-adfr-min-fps-3-command = [
				//15Hz
				39 00 00 40 00 00 04 FF 5A A5 2D
				39 00 00 40 00 00 03 ED 04 00
				39 00 00 40 00 00 03 8F 05 00
				15 00 00 40 00 00 02 A4 00
				15 00 00 40 00 00 02 A5 02
				39 00 00 40 00 00 03 AD 00 00
				39 00 00 00 00 00 04 FF 5A A5 00
			];

			qcom,mdss-dsi-bigdc-adfr-min-fps-4-command = [
				//10Hz
				39 00 00 40 00 00 04 FF 5A A5 2D
				39 00 00 40 00 00 03 ED 04 00
				39 00 00 40 00 00 03 8F 08 00
				15 00 00 40 00 00 02 A4 00
				15 00 00 40 00 00 02 A5 02
				39 00 00 40 00 00 03 AD 00 00
				39 00 00 00 00 00 04 FF 5A A5 00
			];

			qcom,mdss-dsi-bigdc-adfr-min-fps-5-command = [
				//5Hz
				39 00 00 40 00 00 04 FF 5A A5 2D
				39 00 00 40 00 00 03 ED 04 00
				39 00 00 40 00 00 03 8F 11 00
				15 00 00 40 00 00 02 A4 00
				15 00 00 40 00 00 02 A5 02
				39 00 00 40 00 00 03 AD 00 00
				39 00 00 00 00 00 04 FF 5A A5 00
			];

			qcom,mdss-dsi-bigdc-adfr-min-fps-6-command = [
				//1Hz
				39 00 00 40 00 00 04 FF 5A A5 2D
				39 00 00 40 00 00 03 ED 04 00
				39 00 00 40 00 00 03 8F 59 00
				15 00 00 40 00 00 02 A4 02
				15 00 00 40 00 00 02 A5 02
				15 00 00 40 00 00 02 A6 08
				15 00 00 40 00 00 02 A7 11
				39 00 00 40 00 00 03 AD 00 02
				15 00 00 40 00 00 02 AE 02
				39 00 00 00 00 00 04 FF 5A A5 00
			];

			qcom,mdss-dsi-adfr-pre-switch-command-state = "dsi_hs_mode";
			qcom,mdss-dsi-adfr-min-fps-0-command-state = "dsi_hs_mode";
			qcom,mdss-dsi-adfr-min-fps-1-command-state = "dsi_hs_mode";
			qcom,mdss-dsi-adfr-min-fps-2-command-state = "dsi_hs_mode";
			qcom,mdss-dsi-adfr-min-fps-3-command-state = "dsi_hs_mode";
			qcom,mdss-dsi-adfr-min-fps-4-command-state = "dsi_hs_mode";
			qcom,mdss-dsi-adfr-min-fps-5-command-state = "dsi_hs_mode";
			qcom,mdss-dsi-adfr-min-fps-6-command-state = "dsi_hs_mode";
			qcom,mdss-dsi-hpwm-adfr-min-fps-0-command-state = "dsi_hs_mode";
			qcom,mdss-dsi-hpwm-adfr-min-fps-1-command-state = "dsi_hs_mode";
			qcom,mdss-dsi-hpwm-adfr-min-fps-2-command-state = "dsi_hs_mode";
			qcom,mdss-dsi-hpwm-adfr-min-fps-3-command-state = "dsi_hs_mode";
			qcom,mdss-dsi-hpwm-adfr-min-fps-4-command-state = "dsi_hs_mode";
			qcom,mdss-dsi-hpwm-adfr-min-fps-5-command-state = "dsi_hs_mode";
			qcom,mdss-dsi-hpwm-adfr-min-fps-6-command-state = "dsi_hs_mode";
			qcom,mdss-dsi-bigdc-adfr-min-fps-0-command-state = "dsi_hs_mode";
			qcom,mdss-dsi-bigdc-adfr-min-fps-1-command-state = "dsi_hs_mode";
			qcom,mdss-dsi-bigdc-adfr-min-fps-2-command-state = "dsi_hs_mode";
			qcom,mdss-dsi-bigdc-adfr-min-fps-3-command-state = "dsi_hs_mode";
			qcom,mdss-dsi-bigdc-adfr-min-fps-4-command-state = "dsi_hs_mode";
			qcom,mdss-dsi-bigdc-adfr-min-fps-5-command-state = "dsi_hs_mode";
			qcom,mdss-dsi-bigdc-adfr-min-fps-6-command-state = "dsi_hs_mode";
		};
		timing@wqhd_sdc_60 {
			/* SDC ADFR */
			qcom,mdss-dsi-h-sync-skew = <1>;
			oplus,adfr-min-fps-mapping-table = <60 30 20 10 5 1>;
			qcom,mdss-dsi-adfr-pre-switch-command = [
				39 00 00 40 00 00 04 FF 5A A5 2D
				39 00 00 40 00 00 03 ED 01 00
				39 00 00 40 00 00 03 83 01 00
				39 00 00 40 00 00 03 8E 01 00
				15 00 00 40 00 00 02 97 00
				15 00 00 40 00 00 02 98 01
				39 00 00 40 00 00 03 A0 00 00
				39 00 00 00 00 00 04 FF 5A A5 00
			];
			qcom,mdss-dsi-adfr-min-fps-0-command = [
				/*60Hz*/
				39 00 00 40 00 00 04 FF 5A A5 2D
				39 00 00 40 00 00 03 ED 01 00
				39 00 00 40 00 00 03 83 01 00
				15 00 00 40 00 00 02 97 00
				15 00 00 40 00 00 02 98 01
				39 00 00 40 00 00 03 A0 00 00
				39 00 00 00 00 00 04 FF 5A A5 00
			];
			qcom,mdss-dsi-adfr-min-fps-1-command = [
				/*30Hz*/
				39 00 00 40 00 00 04 FF 5A A5 2D
				39 00 00 40 00 00 03 ED 01 00
				39 00 00 40 00 00 03 83 03 00
				15 00 00 40 00 00 02 97 00
				15 00 00 40 00 00 02 98 03
				39 00 00 40 00 00 03 A0 00 00
				39 00 00 00 00 00 04 FF 5A A5 00
			];
			qcom,mdss-dsi-adfr-min-fps-2-command = [
				/*20Hz*/
				39 00 00 40 00 00 04 FF 5A A5 2D
				39 00 00 40 00 00 03 ED 01 00
				39 00 00 40 00 00 03 83 05 00
				15 00 00 40 00 00 02 97 00
				15 00 00 40 00 00 02 98 03
				39 00 00 40 00 00 03 A0 00 00
				39 00 00 00 00 00 04 FF 5A A5 00
			];
			qcom,mdss-dsi-adfr-min-fps-3-command = [
				/*10Hz*/
				39 00 00 40 00 00 04 FF 5A A5 2D
				39 00 00 40 00 00 03 ED 01 00
				39 00 00 40 00 00 03 83 0B 00
				15 00 00 40 00 00 02 97 00
				15 00 00 40 00 00 02 98 03
				39 00 00 40 00 00 03 A0 00 00
				39 00 00 00 00 00 04 FF 5A A5 00
			];
			qcom,mdss-dsi-adfr-min-fps-4-command = [
				/*5Hz*/
				39 00 00 40 00 00 04 FF 5A A5 2D
				39 00 00 40 00 00 03 ED 01 00
				39 00 00 40 00 00 03 83 17 00
				15 00 00 40 00 00 02 97 00
				15 00 00 40 00 00 02 98 03
				39 00 00 40 00 00 03 A0 00 00
				39 00 00 00 00 00 04 FF 5A A5 00
			];
			qcom,mdss-dsi-adfr-min-fps-5-command = [
				/*5Hz*/
				39 00 00 40 00 00 04 FF 5A A5 2D
				39 00 00 40 00 00 03 ED 01 00
				39 00 00 40 00 00 03 83 77 00
				15 00 00 40 00 00 02 97 02
				15 00 00 40 00 00 02 98 03
				15 00 00 40 00 00 02 99 0B
				15 00 00 40 00 00 02 9A 17
				39 00 00 40 00 00 03 A0 00 02
				15 00 00 40 00 00 02 A1 02
				39 00 00 00 00 00 04 FF 5A A5 00
			];
			qcom,mdss-dsi-hpwm-adfr-min-fps-0-command = [
				/*60Hz*/
				39 00 00 40 00 00 04 FF 5A A5 2D
				39 00 00 40 00 00 03 ED 01 00
				39 00 00 40 00 00 03 83 01 00
				15 00 00 40 00 00 02 97 00
				15 00 00 40 00 00 02 98 01
				39 00 00 40 00 00 03 A0 00 00
				39 00 00 00 00 00 04 FF 5A A5 00
			];

			qcom,mdss-dsi-hpwm-adfr-min-fps-1-command = [
				//30Hz
				39 00 00 40 00 00 04 FF 5A A5 2D
				39 00 00 40 00 00 03 ED 01 00
				39 00 00 40 00 00 03 83 03 00
				15 00 00 40 00 00 02 97 00
				15 00 00 40 00 00 02 98 03
				39 00 00 40 00 00 03 A0 00 00
				39 00 00 00 00 00 04 FF 5A A5 00
			];

			qcom,mdss-dsi-hpwm-adfr-min-fps-2-command = [
				//20Hz
				39 00 00 40 00 00 04 FF 5A A5 2D
				39 00 00 40 00 00 03 ED 01 00
				39 00 00 40 00 00 03 83 05 00
				15 00 00 40 00 00 02 97 00
				15 00 00 40 00 00 02 98 03
				39 00 00 40 00 00 03 A0 00 00
				39 00 00 00 00 00 04 FF 5A A5 00
			];

			qcom,mdss-dsi-hpwm-adfr-min-fps-3-command = [
				//10Hz
				39 00 00 40 00 00 04 FF 5A A5 2D
				39 00 00 40 00 00 03 ED 01 00
				39 00 00 40 00 00 03 83 0B 00
				15 00 00 40 00 00 02 97 00
				15 00 00 40 00 00 02 98 03
				39 00 00 40 00 00 03 A0 00 00
				39 00 00 00 00 00 04 FF 5A A5 00
			];

			qcom,mdss-dsi-hpwm-adfr-min-fps-4-command = [
				//5Hz
				39 00 00 40 00 00 04 FF 5A A5 2D
				39 00 00 40 00 00 03 ED 01 00
				39 00 00 40 00 00 03 83 17 00
				15 00 00 40 00 00 02 97 00
				15 00 00 40 00 00 02 98 03
				39 00 00 40 00 00 03 A0 00 00
				39 00 00 00 00 00 04 FF 5A A5 00
			];

			qcom,mdss-dsi-hpwm-adfr-min-fps-5-command = [
				//1Hz
				39 00 00 40 00 00 04 FF 5A A5 2D
				39 00 00 40 00 00 03 ED 01 00
				39 00 00 40 00 00 03 83 77 00
				15 00 00 40 00 00 02 97 02
				15 00 00 40 00 00 02 98 03
				15 00 00 40 00 00 02 99 0B
				15 00 00 40 00 00 02 9A 17
				39 00 00 40 00 00 03 A0 00 02
				15 00 00 40 00 00 02 A1 02
				39 00 00 00 00 00 04 FF 5A A5 00
			];
			qcom,mdss-dsi-bigdc-adfr-min-fps-0-command = [
				/*60Hz*/
				39 00 00 40 00 00 04 FF 5A A5 2D
				39 00 00 40 00 00 03 ED 01 00
				39 00 00 40 00 00 03 8E 01 00
				15 00 00 40 00 00 02 97 00
				15 00 00 40 00 00 02 98 01
				39 00 00 40 00 00 03 A0 00 00
				39 00 00 00 00 00 04 FF 5A A5 00
			];

			qcom,mdss-dsi-bigdc-adfr-min-fps-1-command = [
				//30Hz
				39 00 00 40 00 00 04 FF 5A A5 2D
				39 00 00 40 00 00 03 ED 01 00
				39 00 00 40 00 00 03 8E 03 00
				15 00 00 40 00 00 02 97 00
				15 00 00 40 00 00 02 98 03
				39 00 00 40 00 00 03 A0 00 00
				39 00 00 00 00 00 04 FF 5A A5 00
			];

			qcom,mdss-dsi-bigdc-adfr-min-fps-2-command = [
				//20Hz
				39 00 00 40 00 00 04 FF 5A A5 2D
				39 00 00 40 00 00 03 ED 01 00
				39 00 00 40 00 00 03 8E 05 00
				15 00 00 40 00 00 02 97 00
				15 00 00 40 00 00 02 98 03
				39 00 00 40 00 00 03 A0 00 00
				39 00 00 00 00 00 04 FF 5A A5 00
			];

			qcom,mdss-dsi-bigdc-adfr-min-fps-3-command = [
				//10Hz
				39 00 00 40 00 00 04 FF 5A A5 2D
				39 00 00 40 00 00 03 ED 01 00
				39 00 00 40 00 00 03 8E 0B 00
				15 00 00 40 00 00 02 97 00
				15 00 00 40 00 00 02 98 03
				39 00 00 40 00 00 03 A0 00 00
				39 00 00 00 00 00 04 FF 5A A5 00
			];

			qcom,mdss-dsi-bigdc-adfr-min-fps-4-command = [
				//5Hz
				39 00 00 40 00 00 04 FF 5A A5 2D
				39 00 00 40 00 00 03 ED 01 00
				39 00 00 40 00 00 03 8E 17 00
				15 00 00 40 00 00 02 97 00
				15 00 00 40 00 00 02 98 03
				39 00 00 40 00 00 03 A0 00 00
				39 00 00 00 00 00 04 FF 5A A5 00
			];

			qcom,mdss-dsi-bigdc-adfr-min-fps-5-command = [
				//1Hz
				39 00 00 40 00 00 04 FF 5A A5 2D
				39 00 00 40 00 00 03 ED 01 00
				39 00 00 40 00 00 03 8E 77 00
				15 00 00 40 00 00 02 97 02
				15 00 00 40 00 00 02 98 03
				15 00 00 40 00 00 02 99 0B
				15 00 00 40 00 00 02 9A 17
				39 00 00 40 00 00 03 A0 00 02
				15 00 00 40 00 00 02 A1 02
				39 00 00 00 00 00 04 FF 5A A5 00
			];

			qcom,mdss-dsi-adfr-pre-switch-command-state = "dsi_hs_mode";
			qcom,mdss-dsi-adfr-min-fps-0-command-state = "dsi_hs_mode";
			qcom,mdss-dsi-adfr-min-fps-1-command-state = "dsi_hs_mode";
			qcom,mdss-dsi-adfr-min-fps-2-command-state = "dsi_hs_mode";
			qcom,mdss-dsi-adfr-min-fps-3-command-state = "dsi_hs_mode";
			qcom,mdss-dsi-adfr-min-fps-4-command-state = "dsi_hs_mode";
			qcom,mdss-dsi-adfr-min-fps-5-command-state = "dsi_hs_mode";
			qcom,mdss-dsi-hpwm-adfr-min-fps-0-command-state = "dsi_hs_mode";
			qcom,mdss-dsi-hpwm-adfr-min-fps-1-command-state = "dsi_hs_mode";
			qcom,mdss-dsi-hpwm-adfr-min-fps-2-command-state = "dsi_hs_mode";
			qcom,mdss-dsi-hpwm-adfr-min-fps-3-command-state = "dsi_hs_mode";
			qcom,mdss-dsi-hpwm-adfr-min-fps-4-command-state = "dsi_hs_mode";
			qcom,mdss-dsi-hpwm-adfr-min-fps-5-command-state = "dsi_hs_mode";
			qcom,mdss-dsi-bigdc-adfr-min-fps-0-command-state = "dsi_hs_mode";
			qcom,mdss-dsi-bigdc-adfr-min-fps-1-command-state = "dsi_hs_mode";
			qcom,mdss-dsi-bigdc-adfr-min-fps-2-command-state = "dsi_hs_mode";
			qcom,mdss-dsi-bigdc-adfr-min-fps-3-command-state = "dsi_hs_mode";
			qcom,mdss-dsi-bigdc-adfr-min-fps-4-command-state = "dsi_hs_mode";
			qcom,mdss-dsi-bigdc-adfr-min-fps-5-command-state = "dsi_hs_mode";
		};
		timing@wqhd_oplus_120 {
			/* OPLUS ADFR */
			qcom,mdss-dsi-h-sync-skew = <2>;
			oplus,adfr-min-fps-mapping-table = <120 30>;

			qcom,mdss-dsi-adfr-pre-switch-command = [
				39 00 00 40 00 00 04 FF 5A A5 2D
				39 00 00 40 00 00 19 EF 00 00 00 00 00 00 00 00 00 00 00 00 00 00 00 00 00 00 00 00 02 00 00 00
				39 00 00 00 00 00 04 FF 5A A5 00
			];
			qcom,mdss-dsi-adfr-min-fps-0-command = [
				/*120Hz*/
				39 00 00 40 00 00 04 FF 5A A5 2D
				39 00 00 40 00 00 19 EF 00 00 00 00 00 00 00 00 00 00 00 00 00 00 00 00 00 00 00 00 02 00 00 00
				39 00 00 00 00 00 04 FF 5A A5 00
			];
			qcom,mdss-dsi-adfr-min-fps-1-command = [
				/*30Hz*/
				39 00 00 40 00 00 04 FF 5A A5 2D
				39 00 00 40 00 00 19 EF 00 00 00 00 00 00 00 00 00 00 00 00 00 00 00 07 00 00 00 00 02 00 00 00
				39 00 00 00 00 00 04 FF 5A A5 00
			];
			qcom,mdss-dsi-hpwm-adfr-min-fps-0-command = [
				/*120Hz*/
				39 00 00 40 00 00 04 FF 5A A5 2D
				39 00 00 40 00 00 19 EF 00 00 00 00 00 00 00 00 00 00 00 00 00 00 00 00 00 00 00 00 02 00 00 00
				39 00 00 00 00 00 04 FF 5A A5 00
			];
			qcom,mdss-dsi-hpwm-adfr-min-fps-1-command = [
				/*30Hz*/
				39 00 00 40 00 00 04 FF 5A A5 2D
				39 00 00 40 00 00 19 EF 00 00 00 00 00 00 00 00 00 00 00 00 00 00 00 07 00 00 00 00 02 00 00 00
				39 00 00 00 00 00 04 FF 5A A5 00
			];
			qcom,mdss-dsi-bigdc-adfr-min-fps-0-command = [
				/*120Hz*/
				39 00 00 40 00 00 04 FF 5A A5 2D
				39 00 00 40 00 00 19 EF 00 00 00 00 00 00 00 00 00 00 00 00 00 00 00 00 00 00 00 00 02 00 00 00
				39 00 00 00 00 00 04 FF 5A A5 00
			];
			qcom,mdss-dsi-bigdc-adfr-min-fps-1-command = [
				/*30Hz*/
				39 00 00 40 00 00 04 FF 5A A5 2D
				39 00 00 40 00 00 19 EF 00 00 00 00 00 00 00 00 00 00 00 00 00 00 00 07 00 00 00 00 02 00 00 00
				39 00 00 00 00 00 04 FF 5A A5 00
			];
			qcom,mdss-dsi-qsync-off-commands = [
				/*120Hz*/
				39 00 00 40 00 00 04 FF 5A A5 2D
				39 00 00 40 00 00 19 EF 00 00 00 00 00 00 00 00 00 00 00 00 00 00 00 00 00 00 00 00 02 00 00 00
				39 00 00 00 00 00 04 FF 5A A5 00
			];

			qcom,mdss-dsi-adfr-pre-switch-command-state = "dsi_hs_mode";
			qcom,mdss-dsi-adfr-min-fps-0-command-state = "dsi_hs_mode";
			qcom,mdss-dsi-adfr-min-fps-1-command-state = "dsi_hs_mode";
			qcom,mdss-dsi-hpwm-adfr-min-fps-0-command-state = "dsi_hs_mode";
			qcom,mdss-dsi-hpwm-adfr-min-fps-1-command-state = "dsi_hs_mode";
			qcom,mdss-dsi-bigdc-adfr-min-fps-0-command-state = "dsi_hs_mode";
			qcom,mdss-dsi-bigdc-adfr-min-fps-1-command-state = "dsi_hs_mode";
			qcom,mdss-dsi-qsync-off-commands-state = "dsi_hs_mode";
		};
	};
};

&dsi_panel_AA569_P_3_A0019_dsc_cmd_evb {
	/* HARDWARE CONFIG */
	qcom,panel-supply-entries = <&oplus_dsi_panel_custom_pwr_supply>;
	qcom,mdss-dsi-panel-controller = <&mdss_dsi0>;
	qcom,platform-te-gpio = <&tlmm 86 0>;
	qcom,platform-reset-gpio = <&tlmm 98 0>;
	oplus,panel-gpio1  = <&pm8550ve_f_gpios 7 0>;

	oplus,panel-reset-position = <0x02>;
	oplus,panel-power-on-sequence = "1", "vddio", "3", "gpio1", "3", "vci", "10";
	oplus,panel-power-off-sequence = "1", "vci", "3", "gpio1", "3", "vddio", "1";

	qcom,panel_voltage_vddi_name = "vddio";
	qcom,panel_voltage_vddi = <1 1750000 1850000 1950000>;
	qcom,panel_voltage_vddr_name = "vci";
	qcom,panel_voltage_vddr = <1 3000000 3200000 3300000>;

	/* BRIGHTNESS CONFIG */
	qcom,mdss-dsi-bl-pmic-control-type = "bl_ctrl_dcs";
	qcom,bl-dsc-cmd-state = "dsi_hs_mode";
	qcom,mdss-dsi-bl-inverted-dbv;
	qcom,mdss-dsi-bl-min-level = <1>;
	qcom,mdss-dsi-bl-max-level = <4094>;
	qcom,mdss-brightness-max-level = <4094>;
	oplus,dsi-bl-normal-max-level = <3515>;
	oplus,dsi-brightness-normal-max-level = <3515>;
	oplus,dsi-brightness-default-level = <1433>;
	oplus,dsi-dc-backlight-threshold = <1102>;
	oplus,dsi-global-hbm-case-id = <1>;
	//oplus,dsi-global-hbm-case23-threshold = <2048>;

	/* ESD CONFIG */
	qcom,esd-check-enabled;
	qcom,mdss-dsi-panel-status-check-mode = "reg_read";
	qcom,mdss-dsi-panel-status-command = [
		06 00 00 00 00 00 01 0A
	];
	qcom,mdss-dsi-panel-status-command-state = "dsi_lp_mode";
	qcom,mdss-dsi-panel-status-value = <
		0x9C
	>;
	qcom,mdss-dsi-panel-status-read-length = <1>;
	oplus,mdss-dsi-panel-status-match-modes = <0x00000000>;

	/* FACTORY CONFIG */
	oplus,mdss-dsi-vendor-name = "A0019";
	oplus,mdss-dsi-manufacture = "P_3";
	oplus,color_vivid_status;
	oplus,color_srgb_status;
	//oplus,color_softiris_status;
	oplus,color_oplus_calibrate_status;
	oplus,color_dual_brightness_status;
	oplus,color_2nit_status;
	oplus,color_loading_status;
	//oplus,color_nature_profession_status;
	oplus,mdss-dsi-panel-type = <0>;

	/* OPLUS FEATURES CONFIG */
	oplus,dp-enabled;
	//oplus,dsi-cabc-enabled;
	//oplus,dsi-dre-enabled;
	oplus,dsi-serial-number-enabled;
	//oplus,dsi-serial-number-lock;
	oplus,dsi-serial-number-switch-page;
	oplus,dsi-serial-number-reg= <0x82>;
	oplus,dsi-serial-number-index= <0>;
	oplus,dsi-serial-number-read-count= <7>;

	/* adfr config */
	oplus,adfr-config = <0x1041>;  // 0b0001'0000'0100'0001
	oplus,adfr-test-te-gpio = <&tlmm 85 0>;
	/* just for qsync enable */
	qcom,qsync-enable;
	qcom,mdss-dsi-qsync-min-refresh-rate = <30>;

	oplus,pwm-switch-support;
	oplus,pwm-switch-backlight-threshold = <1100>;
	oplus,pwm-onepulse-support;
	oplus,pwm-onepulse-backlight-threshold = <1100>;

	/* ofp config */
	oplus,ofp-fp-type = <0xc0>;
	oplus,ofp-longrui-aod-config = <0x02>;
	oplus,ofp-need-to-bypass-gamut;
	oplus,ofp-need-to-wait-data-before-aod-on;

	/* SPR CONFIG */
	qcom,spr-pack-type = "pentile";
};
